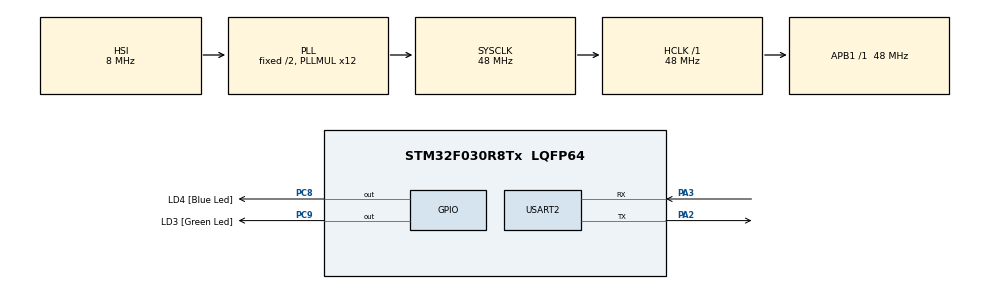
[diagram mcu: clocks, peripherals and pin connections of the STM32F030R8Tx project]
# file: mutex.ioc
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Mcu.Family=STM32F0
VP_SYS_VS_tim6.Mode=TIM6
FREERTOS.Tasks01=defaultTask,0,128,StartDefaultTask,Default,NULL,Dynamic,NULL,NULL
PC9.GPIO_Label=LD3 [Green Led]
PA14.GPIO_Label=SWCLK
PC8.Signal=GPIO_Output
NVIC.USART2_IRQn=true\:3\:0\:false\:false\:true\:true\:true\:true
RCC.SYSCLKSource=RCC_SYSCLKSOURCE_PLLCLK
ProjectManager.StackSize=0x400
NVIC.TIM6_IRQn=true\:0\:0\:false\:false\:true\:false\:false\:true
PC8.GPIO_Label=LD4 [Blue Led]
PA3.Mode=Asynchronous
PA13.Signal=SYS_SWDIO
ProjectManager.TargetToolchain=STM32CubeIDE
RCC.HCLKFreq_Value=48000000
RCC.AHBFreq_Value=48000000
board=STM32F0308-DISCO
USART2.VirtualMode-Asynchronous=VM_ASYNC
RCC.PLLMUL=RCC_PLL_MUL12
PA14.Mode=Serial_Wire
VP_FREERTOS_VS_CMSIS_V1.Mode=CMSIS_V1
PA13.Mode=Serial_Wire
Mcu.Name=STM32F030R8Tx
PA2.Signal=USART2_TX
PA13.GPIO_Label=SWDIO
RCC.SYSCLKFreq_VALUE=48000000
Mcu.Package=LQFP64
NVIC.TimeBase=TIM6_IRQn
NVIC.TimeBaseIP=TIM6
PA14.Signal=SYS_SWCLK
ProjectManager.HeapSize=0x200
RCC.APB1TimFreq_Value=48000000
PA2.Mode=Asynchronous
PC9.Signal=GPIO_Output
RCC.APB1Freq_Value=48000000
PA3.Signal=USART2_RX

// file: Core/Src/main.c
/* USER CODE BEGIN Header */
/**
  ******************************************************************************
  * @file           : main.c
  * @brief          : Main program body
  ******************************************************************************
  * @attention
  *
  * <h2><center>&copy; Copyright (c) 2021 STMicroelectronics.
  * All rights reserved.</center></h2>
  *
  * This software component is licensed by ST under BSD 3-Clause license,
  * the "License"; You may not use this file except in compliance with the
  * License. You may obtain a copy of the License at:
  *                        opensource.org/licenses/BSD-3-Clause
  *
  ******************************************************************************
  */
/* USER CODE END Header */
#include "main.h"
#include "FreeRTOS.h"
#include "task.h"
#include "timers.h"
#include "queue.h"
#include "semphr.h"
#include "event_groups.h"
#include "string.h"

UART_HandleTypeDef huart2;

xTaskHandle Sender_HPT_Task_Handler;
xTaskHandle Sender_LPT_Task_Handler;
xTaskHandle Receiver_Task_Handler;

xQueueHandle SimpleQueue;

void Sender_HPT_Task(void *arguments);
void Sender_LPT_Task(void *arguments);
void Receiver_Task(void *arguments);

void SystemClock_Config(void);
static void MX_GPIO_Init(void);
static void MX_USART2_UART_Init(void);
void StartDefaultTask(void const * argument);

/* USER CODE BEGIN PFP */
uint8_t Rx_data = 0;
/* USER CODE END PFP */

int main(void)
{

  /* MCU Configuration--------------------------------------------------------*/

  /* Reset of all peripherals, Initializes the Flash interface and the Systick. */
  HAL_Init();

  /* Configure the system clock */
  SystemClock_Config();

  /* Initialize all configured peripherals */
  MX_GPIO_Init();
  MX_USART2_UART_Init();
  /* USER CODE BEGIN 2 */
  SimpleQueue = xQueueCreate(5,sizeof(int));
  if(SimpleQueue == 0)
  {
	  char *str1 = "Unable to create integer queue\n\n";
	  HAL_UART_Transmit(&huart2, str1, strlen(str1), HAL_MAX_DELAY);
  }
  /* USER CODE END 2 */
  xTaskCreate(Sender_HPT_Task, "hpt", 128, NULL, 3, Sender_HPT_Task_Handler);
  xTaskCreate(Sender_LPT_Task, "lpt", 128, (void *)111, 2, Sender_LPT_Task_Handler);
  xTaskCreate(Receiver_Task, "rcv", 128, NULL, 1, Receiver_Task_Handler);
  HAL_UART_Receive_IT(&huart2, &Rx_data, 1);
  vTaskStartScheduler();

  /* Start scheduler */
  //osKernelStart();

  /* We should never get here as control is now taken by the scheduler */
  /* Infinite loop */
  while (1)
  {

  }
}

void SystemClock_Config(void)
{
  RCC_OscInitTypeDef RCC_OscInitStruct = {0};
  RCC_ClkInitTypeDef RCC_ClkInitStruct = {0};

  /** Initializes the RCC Oscillators according to the specified parameters
  * in the RCC_OscInitTypeDef structure.
  */
  RCC_OscInitStruct.OscillatorType = RCC_OSCILLATORTYPE_HSI;
  RCC_OscInitStruct.HSIState = RCC_HSI_ON;
  RCC_OscInitStruct.HSICalibrationValue = RCC_HSICALIBRATION_DEFAULT;
  RCC_OscInitStruct.PLL.PLLState = RCC_PLL_ON;
  RCC_OscInitStruct.PLL.PLLSource = RCC_PLLSOURCE_HSI;
  RCC_OscInitStruct.PLL.PLLMUL = RCC_PLL_MUL12;
  RCC_OscInitStruct.PLL.PREDIV = RCC_PREDIV_DIV1;
  if (HAL_RCC_OscConfig(&RCC_OscInitStruct) != HAL_OK)
  {
    Error_Handler();
  }
  /** Initializes the CPU, AHB and APB buses clocks
  */
  RCC_ClkInitStruct.ClockType = RCC_CLOCKTYPE_HCLK|RCC_CLOCKTYPE_SYSCLK
                              |RCC_CLOCKTYPE_PCLK1;
  RCC_ClkInitStruct.SYSCLKSource = RCC_SYSCLKSOURCE_PLLCLK;
  RCC_ClkInitStruct.AHBCLKDivider = RCC_SYSCLK_DIV1;
  RCC_ClkInitStruct.APB1CLKDivider = RCC_HCLK_DIV1;

  if (HAL_RCC_ClockConfig(&RCC_ClkInitStruct, FLASH_LATENCY_1) != HAL_OK)
  {
    Error_Handler();
  }
}

static void MX_USART2_UART_Init(void)
{

  huart2.Instance = USART2;
  huart2.Init.BaudRate = 38400;
  huart2.Init.WordLength = UART_WORDLENGTH_8B;
  huart2.Init.StopBits = UART_STOPBITS_1;
  huart2.Init.Parity = UART_PARITY_NONE;
  huart2.Init.Mode = UART_MODE_TX_RX;
  huart2.Init.HwFlowCtl = UART_HWCONTROL_NONE;
  huart2.Init.OverSampling = UART_OVERSAMPLING_16;
  huart2.Init.OneBitSampling = UART_ONE_BIT_SAMPLE_DISABLE;
  huart2.AdvancedInit.AdvFeatureInit = UART_ADVFEATURE_NO_INIT;
  if (HAL_UART_Init(&huart2) != HAL_OK)
  {
    Error_Handler();
  }

}

static void MX_GPIO_Init(void)
{
  GPIO_InitTypeDef GPIO_InitStruct = {0};

  /* GPIO Ports Clock Enable */
  __HAL_RCC_GPIOA_CLK_ENABLE();
  __HAL_RCC_GPIOC_CLK_ENABLE();

  /*Configure GPIO pin Output Level */
  HAL_GPIO_WritePin(GPIOC, LD4_Pin|LD3_Pin, GPIO_PIN_RESET);

  /*Configure GPIO pins : LD4_Pin LD3_Pin */
  GPIO_InitStruct.Pin = LD4_Pin|LD3_Pin;
  GPIO_InitStruct.Mode = GPIO_MODE_OUTPUT_PP;
  GPIO_InitStruct.Pull = GPIO_NOPULL;
  GPIO_InitStruct.Speed = GPIO_SPEED_FREQ_LOW;
  HAL_GPIO_Init(GPIOC, &GPIO_InitStruct);

}

 /**
  * @brief  Period elapsed callback in non blocking mode
  * @note   This function is called  when TIM6 interrupt took place, inside
  * HAL_TIM_IRQHandler(). It makes a direct call to HAL_IncTick() to increment
  * a global variable "uwTick" used as application time base.
  * @param  htim : TIM handle
  * @retval None
  */
void HAL_TIM_PeriodElapsedCallback(TIM_HandleTypeDef *htim)
{
  if (htim->Instance == TIM6) {
    HAL_IncTick();
  }
}

void Error_Handler(void)
{
  __disable_irq();
  while (1)
  {
  }
}

/************************ (C) COPYRIGHT STMicroelectronics *****END OF FILE****/
